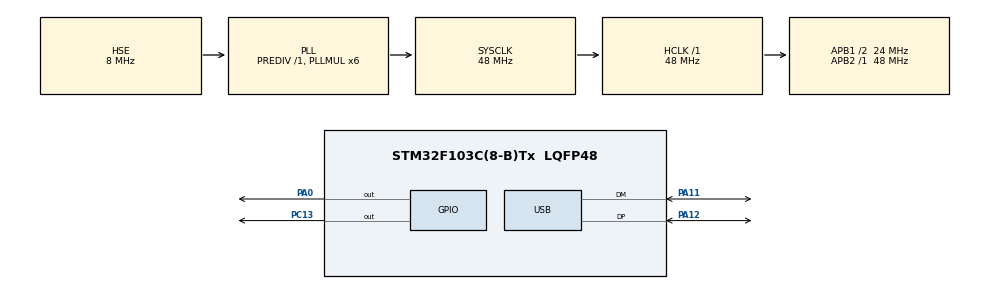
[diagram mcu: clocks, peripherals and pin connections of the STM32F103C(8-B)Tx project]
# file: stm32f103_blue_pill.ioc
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FREERTOS.MEMORY_ALLOCATION=1
FREERTOS.Tasks01=defaultTask,0,128,StartDefaultTask,Default,NULL,Static,defaultTaskBuffer,defaultTaskControlBlock;blinking,-3,128,blinkingTask,As external,NULL,Static,blinkingBuffer,blinkingControlBlock
FREERTOS.configTOTAL_HEAP_SIZE=8162
Mcu.Family=STM32F1
Mcu.Name=STM32F103C(8-B)Tx
Mcu.Package=LQFP48
NVIC.PriorityGroup=NVIC_PRIORITYGROUP_4
NVIC.TIM1_UP_IRQn=true\:0\:0\:false\:false\:true\:false\:false\:true
NVIC.TimeBase=TIM1_UP_IRQn
NVIC.TimeBaseIP=TIM1
NVIC.USB_LP_CAN1_RX0_IRQn=true\:5\:0\:false\:false\:true\:true\:false\:true
PA0-WKUP.Signal=GPIO_Output
PA11.Mode=Device
PA11.Signal=USB_DM
PA12.Mode=Device
PA12.Signal=USB_DP
PA13.Mode=Serial_Wire
PA13.Signal=SYS_JTMS-SWDIO
PA14.Mode=Serial_Wire
PA14.Signal=SYS_JTCK-SWCLK
PC13-TAMPER-RTC.Signal=GPIO_Output
PC14-OSC32_IN.Mode=LSE-External-Oscillator
PC14-OSC32_IN.Signal=RCC_OSC32_IN
PC15-OSC32_OUT.Mode=LSE-External-Oscillator
PC15-OSC32_OUT.Signal=RCC_OSC32_OUT
PD0-OSC_IN.Mode=HSE-External-Oscillator
PD0-OSC_IN.Signal=RCC_OSC_IN
PD1-OSC_OUT.Mode=HSE-External-Oscillator
PD1-OSC_OUT.Signal=RCC_OSC_OUT
ProjectManager.HeapSize=0x200
ProjectManager.StackSize=0x400
ProjectManager.TargetToolchain=Makefile
RCC.AHBFreq_Value=48000000
RCC.APB1CLKDivider=RCC_HCLK_DIV2
RCC.APB1Freq_Value=24000000
RCC.APB1TimFreq_Value=48000000
RCC.APB2Freq_Value=48000000
RCC.APB2TimFreq_Value=48000000
RCC.DATA_CACHE_ENABLE=1
RCC.HCLKFreq_Value=48000000
RCC.INSTRUCTION_CACHE_ENABLE=1
RCC.MSIAutoCalibration=DISABLED
RCC.MSICalibrationValue=0
RCC.PLLMUL=RCC_PLL_MUL6
RCC.PLLSourceVirtual=RCC_PLLSOURCE_HSE
RCC.PWR_Regulator_Voltage_Scale=PWR_REGULATOR_VOLTAGE_SCALE1
RCC.SYSCLKFreq_VALUE=48000000
RCC.SYSCLKSource=RCC_SYSCLKSOURCE_PLLCLK
RCC.USBFreq_Value=48000000
USB_DEVICE.CLASS_NAME_FS=CDC
USB_DEVICE.VirtualMode=Cdc
USB_DEVICE.VirtualModeFS=Cdc_FS
VP_FREERTOS_VS_CMSIS_V1.Mode=CMSIS_V1
VP_SYS_VS_tim1.Mode=TIM1
VP_USB_DEVICE_VS_USB_DEVICE_CDC_FS.Mode=CDC_FS
board=custom

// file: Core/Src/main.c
/* USER CODE BEGIN Header */
/**
  ******************************************************************************
  * @file           : main.c
  * @brief          : Main program body
  ******************************************************************************
  * @attention
  *
  * <h2><center>&copy; Copyright (c) 2019 STMicroelectronics.
  * All rights reserved.</center></h2>
  *
  * This software component is licensed by ST under Ultimate Liberty license
  * SLA0044, the "License"; You may not use this file except in compliance with
  * the License. You may obtain a copy of the License at:
  *                             www.st.com/SLA0044
  *
  ******************************************************************************
  */
/* USER CODE END Header */

#include "main.h"
#include "cmsis_os.h"
#include "usb_device.h"
#include "gpio.h"

void SystemClock_Config(void);
void MX_FREERTOS_Init(void);

int main(void)
{

  /* MCU Configuration--------------------------------------------------------*/

  /* Reset of all peripherals, Initializes the Flash interface and the Systick. */
  HAL_Init();

  /* Configure the system clock */
  SystemClock_Config();

  /* Initialize all configured peripherals */
  MX_GPIO_Init();

  /* Call init function for freertos objects (in freertos.c) */
  MX_FREERTOS_Init();

  /* Start scheduler */
  osKernelStart();

  /* We should never get here as control is now taken by the scheduler */

  /* Infinite loop */
  while (1)
  {

  }
}

void SystemClock_Config(void)
{
  RCC_OscInitTypeDef RCC_OscInitStruct = {0};
  RCC_ClkInitTypeDef RCC_ClkInitStruct = {0};
  RCC_PeriphCLKInitTypeDef PeriphClkInit = {0};

  /** Initializes the CPU, AHB and APB busses clocks
  */
  RCC_OscInitStruct.OscillatorType = RCC_OSCILLATORTYPE_HSE;
  RCC_OscInitStruct.HSEState = RCC_HSE_ON;
  RCC_OscInitStruct.HSEPredivValue = RCC_HSE_PREDIV_DIV1;
  RCC_OscInitStruct.HSIState = RCC_HSI_ON;
  RCC_OscInitStruct.PLL.PLLState = RCC_PLL_ON;
  RCC_OscInitStruct.PLL.PLLSource = RCC_PLLSOURCE_HSE;
  RCC_OscInitStruct.PLL.PLLMUL = RCC_PLL_MUL6;
  if (HAL_RCC_OscConfig(&RCC_OscInitStruct) != HAL_OK)
  {
    Error_Handler();
  }
  /** Initializes the CPU, AHB and APB busses clocks
  */
  RCC_ClkInitStruct.ClockType = RCC_CLOCKTYPE_HCLK|RCC_CLOCKTYPE_SYSCLK
                              |RCC_CLOCKTYPE_PCLK1|RCC_CLOCKTYPE_PCLK2;
  RCC_ClkInitStruct.SYSCLKSource = RCC_SYSCLKSOURCE_PLLCLK;
  RCC_ClkInitStruct.AHBCLKDivider = RCC_SYSCLK_DIV1;
  RCC_ClkInitStruct.APB1CLKDivider = RCC_HCLK_DIV2;
  RCC_ClkInitStruct.APB2CLKDivider = RCC_HCLK_DIV1;

  if (HAL_RCC_ClockConfig(&RCC_ClkInitStruct, FLASH_LATENCY_1) != HAL_OK)
  {
    Error_Handler();
  }
  PeriphClkInit.PeriphClockSelection = RCC_PERIPHCLK_USB;
  PeriphClkInit.UsbClockSelection = RCC_USBCLKSOURCE_PLL;
  if (HAL_RCCEx_PeriphCLKConfig(&PeriphClkInit) != HAL_OK)
  {
    Error_Handler();
  }
}

void HAL_TIM_PeriodElapsedCallback(TIM_HandleTypeDef *htim)
{
  if (htim->Instance == TIM1) {
    HAL_IncTick();
  }
}

void Error_Handler(void)
{
  /* USER CODE BEGIN Error_Handler_Debug */
  /* User can add his own implementation to report the HAL error return state */
  HAL_GPIO_WritePin(GPIOC, GPIO_PIN_13, GPIO_PIN_SET);

  for (int i = 0; i < 3; ++i)
  {
    osDelay(50);
    HAL_GPIO_TogglePin(GPIOC, GPIO_PIN_13);
    osDelay(100);
    HAL_GPIO_TogglePin(GPIOC, GPIO_PIN_13);
    osDelay(200);
    HAL_GPIO_TogglePin(GPIOC, GPIO_PIN_13);
    osDelay(200);
    HAL_GPIO_TogglePin(GPIOC, GPIO_PIN_13);
  }

  HAL_GPIO_WritePin(GPIOC, GPIO_PIN_13, GPIO_PIN_RESET);
  /* USER CODE END Error_Handler_Debug */
}

/************************ (C) COPYRIGHT STMicroelectronics *****END OF FILE****/

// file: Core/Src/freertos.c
/* USER CODE BEGIN Header */
/**
  ******************************************************************************
  * File Name          : freertos.c
  * Description        : Code for freertos applications
  ******************************************************************************
  * @attention
  *
  * <h2><center>&copy; Copyright (c) 2019 STMicroelectronics.
  * All rights reserved.</center></h2>
  *
  * This software component is licensed by ST under Ultimate Liberty license
  * SLA0044, the "License"; You may not use this file except in compliance with
  * the License. You may obtain a copy of the License at:
  *                             www.st.com/SLA0044
  *
  ******************************************************************************
  */
/* USER CODE END Header */

#include "FreeRTOS.h"
#include "task.h"
#include "main.h"
#include "cmsis_os.h"

osThreadId defaultTaskHandle;
uint32_t defaultTaskBuffer[ 128 ];
osStaticThreadDef_t defaultTaskControlBlock;
osThreadId blinkingHandle;
uint32_t blinkingBuffer[ 128 ];
osStaticThreadDef_t blinkingControlBlock;

void StartDefaultTask(void const * argument);
extern void blinkingTask(void const * argument);

extern void MX_USB_DEVICE_Init(void);
void MX_FREERTOS_Init(void); /* (MISRA C 2004 rule 8.1) */

/* GetIdleTaskMemory prototype (linked to static allocation support) */
void vApplicationGetIdleTaskMemory( StaticTask_t **ppxIdleTaskTCBBuffer, StackType_t **ppxIdleTaskStackBuffer, uint32_t *pulIdleTaskStackSize );

/* USER CODE BEGIN GET_IDLE_TASK_MEMORY */
static StaticTask_t xIdleTaskTCBBuffer;
static StackType_t xIdleStack[configMINIMAL_STACK_SIZE];

void vApplicationGetIdleTaskMemory( StaticTask_t **ppxIdleTaskTCBBuffer, StackType_t **ppxIdleTaskStackBuffer, uint32_t *pulIdleTaskStackSize )
{
  *ppxIdleTaskTCBBuffer = &xIdleTaskTCBBuffer;
  *ppxIdleTaskStackBuffer = &xIdleStack[0];
  *pulIdleTaskStackSize = configMINIMAL_STACK_SIZE;
  /* place for user code */
}
/* USER CODE END GET_IDLE_TASK_MEMORY */

void MX_FREERTOS_Init(void) {

  /* Create the thread(s) */
  /* definition and creation of defaultTask */
  osThreadStaticDef(defaultTask, StartDefaultTask, osPriorityNormal, 0, 128, defaultTaskBuffer, &defaultTaskControlBlock);
  defaultTaskHandle = osThreadCreate(osThread(defaultTask), NULL);

  /* definition and creation of blinking */
  osThreadStaticDef(blinking, blinkingTask, osPriorityIdle, 0, 128, blinkingBuffer, &blinkingControlBlock);
  blinkingHandle = osThreadCreate(osThread(blinking), NULL);

}

void StartDefaultTask(void const * argument)
{

  /* init code for USB_DEVICE */
  MX_USB_DEVICE_Init();

  for(;;)
  {
    osDelay(1);
  }
}

/************************ (C) COPYRIGHT STMicroelectronics *****END OF FILE****/
